# platform_designer_hps_system_hps_0_hps register map
Vendor: default_vendor.com; File version: 0.0
Registers are 32-bit, read-write, reset 0x0 unless marked. A register's access mark holds for its fields unless they carry their own. Offsets are from the block's base; [hi:lo] are bit positions; <NAME> marks a mode.

## emac0 (part 1 of 5) — Registers in the EMAC module.
Base 0xFF700000
Same registers: emac1 0xFF702000
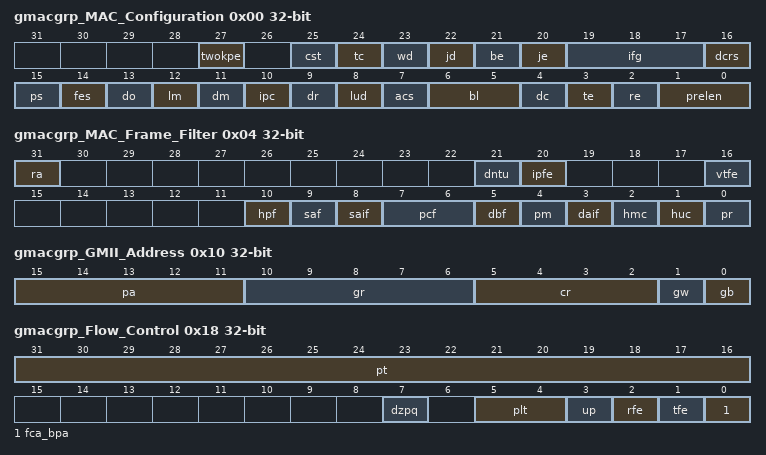
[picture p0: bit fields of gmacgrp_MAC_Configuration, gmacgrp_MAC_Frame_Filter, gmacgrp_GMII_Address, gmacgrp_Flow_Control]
0x00 gmacgrp_MAC_Configuration — The MAC Configuration register establishes receive and transmit operating modes.
  [27] twokpe — When set, the MAC considers all frames, with up to 2,000 bytes length, as normal packets. When Bit 20 (Jumbo Enable) is not set, the MAC considers all received frames of size more than 2K bytes as Giant frames. When this bit is reset and Bit 20 (Jumbo Enable) is not set, the MAC considers all received frames of size more than 1,518 bytes (1,522 bytes for tagged) as Giant frames. When Bit 20 (Jumbo Enable) is set, setting this bit has no effect on Giant Frame status.
  [25] cst — When set, the last 4 bytes (FCS) of all frames of Ether type (type field greater than 0x0600) are stripped and dropped before forwarding the frame to the application. This function is not valid when the IP Checksum Engine (Type 1) is enabled in the MAC receiver.
    0=disabled; 1=enabled
  [24] tc — When set, this bit enables the transmission of duplex mode, link speed, and link up or down information to the PHY in the RGMII. When this bit is reset, no such information is driven to the PHY.
    1=enabled; 0=disabled
  [23] wd — When this bit is set, the MAC disables the watchdog timer on the receiver. The MAC can receive frames of up to 16,384 bytes. When this bit is reset, the MAC does not allow more than 2,048 bytes (10,240 if JE is set high) of the frame being received. The MAC cuts off any bytes received after 2,048 bytes.
    0=enabled; 1=disabled
  [22] jd — When this bit is set, the MAC disables the jabber timer on the transmitter. The MAC can transfer frames of up to 16,384 bytes. When this bit is reset, the MAC cuts off the transmitter if the application sends out more than 2,048 bytes of data (10,240 if JE is set high) during transmission.
    0=enabled; 1=disabled
  [21] be — When this bit is set, the MAC allows frame bursting during transmission in the GMII half-duplex mode.
    0=disabled; 1=enabled
  [20] je — When this bit is set, the MAC allows Jumbo frames of 9,018 bytes (9,022 bytes for VLAN tagged frames) without reporting a giant frame error in the receive frame status.
    0=disabled; 1=enabled
  [19:17] ifg — These bits control the minimum IFG between frames during transmission. In the half-duplex mode, the minimum IFG can be configured only for 64 bit times (IFG = 100). Lower values are not considered. In the 1000-Mbps mode, the minimum IFG supported is 80 bit times (and above).
    0=ifg96bittimes; 1=ifg88bittimes; 2=ifg80bittimes; 3=ifg72bittimes; 4=ifg64bittimes; 5=ifg56bittimes; 6=ifg48bittimes; 7=ifg40bittimes
  [16] dcrs — When set high, this bit makes the MAC transmitter ignore the (G)MII CRS signal during frame transmission in the half-duplex mode. This request results in no errors generated because of Loss of Carrier or No Carrier during such transmission. When this bit is low, the MAC transmitter generates such errors because of Carrier Sense and can even abort the transmissions.
    0=disabled; 1=enabled
  [15] ps — This bit selects between GMII and MII
    0=gmii1000sel; 1=mii10100sel
  [14] fes — This bit selects the speed in the RMII/RGMII interface: * 0: 10 Mbps * 1: 100 Mbps This bit generates link speed encoding when TC (Bit 24) is set in the RGMII, SMII, or SGMII mode.
    0=speed10; 1=speed100
  [13] do — When this bit is set, the MAC disables the reception of frames when the gmii_txen_o is asserted in the half-duplex mode. When this bit is reset, the MAC receives all packets that are given by the PHY while transmitting. This bit is not applicable if the MAC is operating in the full-duplex mode.
    0=enabled; 1=disabled
  [12] lm — When this bit is set, the MAC operates in the loopback mode at GMII or MII. The (G)MII Receive clock input is required for the loopback to work properly, because the Transmit clock is not looped-back internally.
    0=disabled; 1=enabled
  [11] dm — When this bit is set, the MAC operates in the full-duplex mode where it can transmit and receive simultaneously.
    1=enabled; 0=disabled
  [10] ipc — When this bit is set, the MAC calculates the 16-bit ones complement of the ones complement sum of all received Ethernet frame payloads. It also checks whether the IPv4 Header checksum (assumed to be bytes 2526 or 2930 (VLAN-tagged) of the received Ethernet frame) is correct for the received frame and gives the status in the receive status word. The MAC also appends the 16-bit checksum calculated for the IP header datagram payload (bytes after the IPv4 header) and appends it to the Ethernet frame transferred to the application (when Type 2 COE is deselected). When this bit is reset, this function is disabled. When Type 2 COE is selected, this bit, when set, enables the IPv4 header checksum checking and IPv4 or IPv6 TCP, UDP, or ICMP payload checksum checking. When this bit is reset, the COE function in the receiver is disabled and the corresponding PCE and IP HCE status bits are always cleared.
    1=enabled; 0=disabled
  [9] dr — When this bit is set, the MAC attempts only one transmission. When a collision occurs on the GMII or MII interface, the MAC ignores the current frame transmission and reports a Frame Abort with excessive collision error in the transmit frame status. When this bit is reset, the MAC attempts retries based on the settings of the BL field (Bits [6:5]). This bit is applicable only in the half-duplex mode.
    1=disabled; 0=enabled
  [8] lud — This bit indicates whether the link is up or down during the transmission of configuration in the RGMII, SGMII, or SMII interface
    0=disabled; 1=enabled
  [7] acs — When this bit is set, the MAC strips the Pad or FCS field on the incoming frames only if the value of the length field is less than 1,536 bytes. All received frames with length field greater than or equal to 1,536 bytes are passed to the application without stripping the Pad or FCS field. When this bit is reset, the MAC passes all incoming frames, without modifying them, to the Host.
    0=disabled; 1=enabled
  [6:5] bl — The Back-Off limit determines the random integer number (r) of slot time delays (4,096 bit times for 1000 Mbps and 512 bit times for 10/100 Mbps) for which the MAC waits before rescheduling a transmission attempt during retries after a collision. This bit is applicable only in the half-duplex mode. * 00: k = min (n, 10) * 01: k = min (n, 8) * 10: k = min (n, 4) * 11: k = min (n, 1) where <i> n </i>= retransmission attempt. The random integer <i> r </i> takes the value in the range 0 <= r < kth power of 2
    0=backlimtr10; 1=backlimirt8; 2=backlimitr4; 3=backlimitr1
  [4] dc — When this bit is set, the deferral check function is enabled in the MAC. The MAC issues a Frame Abort status, along with the excessive deferral error bit set in the transmit frame status, when the transmit state machine is deferred for more than 24,288 bit times in the 10 or 100 Mbps mode. If the MAC is configured for 1000 Mbps operation, or if the Jumbo frame mode is enabled in the 10 or 100 Mbps mode, the threshold for deferral is 155,680 bits times. Deferral begins when the transmitter is ready to transmit, but is prevented because of an active carrier sense signal (CRS) on GMII or MII. Defer time is not cumulative. When the transmitter defers for 10,000 bit times, it transmits, collides, backs off, and then defers again after completion of back-off. The deferral timer resets to 0 and restarts. When this bit is reset, the deferral check function is disabled and the MAC defers until the CRS signal goes inactive. This bit is applicable only in the half-duplex mode.
    1=enabled; 0=disabled
  [3] te — When this bit is set, the transmit state machine of the MAC is enabled for transmission on the GMII or MII. When this bit is reset, the MAC transmit state machine is disabled after the completion of the transmission of the current frame, and does not transmit any further frames.
    0=disabled; 1=enabled
  [2] re — When this bit is set, the receiver state machine of the MAC is enabled for receiving frames from the GMII or MII. When this bit is reset, the MAC receive state machine is disabled after the completion of the reception of the current frame, and does not receive any further frames from the GMII or MII.
    0=disabled; 1=enabled
  [1:0] prelen — These bits control the number of preamble bytes that are added to the beginning of every Transmit frame. The preamble reduction occurs only when the MAC is operating
    0=pream7bytes; 1=pream5bytes; 2=pream3bytes
0x04 gmacgrp_MAC_Frame_Filter — The MAC Frame Filter register contains the filter controls for receiving frames. Some of the controls from this register go to the address check block of the MAC, which performs the first level of address filtering. The second level of filtering is performed on the incoming frame, based on other controls such as Pass Bad Frames and Pass Control Frames.
  [31] ra — When this bit is set, the MAC Receiver block passes all received frames, irrespective of whether they pass the address filter or not, to the Application. The result of the SA or DA filtering is updated (pass or fail) in the corresponding bits in the Receive Status Word. When this bit is reset, the Receiver block passes only those frames to the Application that pass the SA or DA address filter.
    0=disabled; 1=enabled
  [21] dntu — When set, this bit enables the MAC to drop the non-TCP or UDP over IP frames. The MAC forward only those frames that are processed by the Layer 4 filter. When reset, this bit enables the MAC to forward all non-TCP or UDP over IP frames.
    0=nodrop; 1=drop
  [20] ipfe — When set, this bit enables the MAC to drop frames that do not match the enabled Layer 3 and Layer 4 filters. If Layer 3 or Layer 4 filters are not enabled for matching, this bit does not have any effect. When reset, the MAC forwards all frames irrespective of the match status of the Layer 3 and Layer 4 filters.
    0=nodrop; 1=drop
  [16] vtfe — When set, this bit enables the MAC to drop VLAN tagged frames that do not match the VLAN Tag comparison. When reset, the MAC forwards all frames irrespective of the match status of the VLAN Tag.
    0=nodrop; 1=drop
  [10] hpf — When this bit is set, it configures the address filter to pass a frame if it matches either the perfect filtering or the hash filtering as set by the HMC or HUC bits. When this bit is low and the HUC or HMC bit is set, the frame is passed only if it matches the Hash filter.
    0=disabled; 1=enabled
  [9] saf — When this bit is set, the MAC compares the SA field of the received frames with the values programmed in the enabled SA registers. If the comparison matches, then the SA Match bit of RxStatus Word is set high. When this bit is set high and the SA filter fails, the MAC drops the frame. When this bit is reset, the MAC forwards the received frame to the application and with the updated SA Match bit of the RxStatus depending on the SA address comparison.
    0=disabled; 1=enabled
  [8] saif — When this bit is set, the Address Check block operates in inverse filtering mode for the SA address comparison. The frames whose SA matches the SA registers are marked as failing the SA Address filter. When this bit is reset, frames whose SA does not match the SA registers are marked as failing the SA Address filter.
    0=disabled; 1=enabled
  [7:6] pcf — These bits control the forwarding of all control frames (including unicast and multicast PAUSE frames). * 00: MAC filters all control frames from reaching the application. * 01: MAC forwards all control frames except PAUSE control frames to application even if they fail the Address filter. * 10: MAC forwards all control frames to application even if they fail the Address Filter. * 11: MAC forwards control frames that pass the Address Filter. The following conditions should be true for the PAUSE control frames processing: * Condition 1: The MAC is in the full-duplex mode and flow control is enabled by setting Bit 2 (RFE) of Register 6 (Flow Control Register) to 1. * Condition 2: The destination address (DA) of the received frame matches the special multicast address or the MAC Address 0 when Bit 3 (UP) of the Register 6 (Flow Control Register) is set. * Condition 3: The Type field of the received frame is 0x8808 and the OPCODE field is 0x0001. This field should be set to 01 only when the Condition 1 is true, that is, the MAC is programmed to operate in the full-duplex mode and the RFE bit is enabled. Otherwise, the PAUSE frame filtering may be inconsistent. When Condition 1 is false, the PAUSE frames are considered as generic control frames. Therefore, to pass all control frames (including PAUSE control frames) when the full-duplex mode and flow control is not enabled, you should set the PCF field to 10 or 11 (as required by the application).
    0=macfltallcfr; 1=macfwdxpause; 2=macfwdfail; 3=macfwdpass
  [5] dbf — When this bit is set, the AFM block filters all incoming broadcast frames. In addition, it overrides all other filter settings. When this bit is reset, the AFM block passes all received broadcast frames.
    0=disabled; 1=enabled
  [4] pm — When set, this bit indicates that all received frames with a multicast destination address (first bit in the destination address field is '1') are passed. When reset, filtering of multicast frame depends on HMC bit.
    0=disabled; 1=enabled
  [3] daif — When this bit is set, the Address Check block operates in inverse filtering mode for the DA address comparison for both unicast and multicast frames. When reset, normal filtering of frames is performed.
    0=disabled; 1=enabled
  [2] hmc — When set, MAC performs destination address filtering of received multicast frames according to the hash table. When reset, the MAC performs a perfect destination address filtering for multicast frames, that is, it compares the DA field with the values programmed in DA registers.
    0=disabled; 1=enabled
  [1] huc — When set, MAC performs destination address filtering of unicast frames according to the hash table. When reset, the MAC performs a perfect destination address filtering for unicast frames, that is, it compares the DA field with the values programmed in DA registers.
    1=enabled; 0=disabled
  [0] pr — When this bit is set, the Address Filter block passes all incoming frames regardless of its destination or source address. The SA or DA Filter Fails status bits of the Receive Status Word are always cleared when PR is set.
    1=enabled; 0=disabled
0x10 gmacgrp_GMII_Address — The GMII Address register controls the management cycles to the external PHY through the management interface.
  [15:11] pa — This field indicates which of the 32 possible PHY devices are being accessed. For RevMII, this field gives the PHY Address of the RevMII block.
  [10:6] gr — These bits select the desired GMII register in the selected PHY device. For RevMII, these bits select the desired CSR register in the RevMII Registers set.
  [5:2] cr — The CSR Clock Range selection determines the frequency of the MDC clock according to the l3_sp_clk frequency used in your design. The suggested range of l3_sp_clk frequency applicable for each value (when Bit[5] = 0) ensures that the MDC clock is approximately between the frequency range 1.0 MHz - 2.5 MHz. When Bit 5 is set, you can achieve MDC clock of frequency higher than the IEEE 802.3 specified frequency limit of 2.5 MHz and program a clock divider of lower value. For example, when l3_sp_clk is of 100 MHz frequency and you program these bits as 1010, then the resultant MDC clock is of 12.5 MHz which is outside the limit of IEEE 802.3 specified range. Only use the values larger than 7 if the interfacing chips support faster MDC clocks.
    0=div42; 1=div62; 2=div16; 3=div26; 4=div102; 5=div124; 8=div4; 9=div6; 10=div8; 11=div10; 12=div12; 13=div14; 14=div16again; 15=div18
  [1] gw — When set, this bit indicates to the PHY or RevMII that this is a Write operation using the GMII Data register. If this bit is not set, it indicates that this is a Read operation, that is, placing the data in the GMII Data register.
    0=disabled; 1=enabled
  [0] gb — This bit should read logic 0 before writing to Register 4 and Register 5. During a PHY or RevMII register access, the software sets this bit to 1'b1 to indicate that a Read or Write access is in progress. The Register 5 is invalid until this bit is cleared by the MAC. Therefore, Register 5 (GMII Data) should be kept valid until the MAC clears this bit during a PHY Write operation. Similarly for a read operation, the contents of Register 5 are not valid until this bit is cleared. The subsequent read or write operation should happen only after the previous operation is complete. Because there is no acknowledgment from the PHY to MAC after a read or write operation is completed, there is no change in the functionality of this bit even when the PHY is not present.
    0=disabled; 1=enabled
0x14 gmacgrp_GMII_Data — The GMII Data register stores Write data to be written to the PHY register located at the address specified in Register 4 (GMII Address Register). This register also stores the Read data from the PHY register located at the address specified by Register 4.
  [15:0] gd — This field contains the 16-bit data value read from the PHY or RevMII after a Management Read operation or the 16-bit data value to be written to the PHY or RevMII before a Management Write operation.
0x18 gmacgrp_Flow_Control — The Flow Control register controls the generation and reception of the Control (Pause Command) frames by the MAC's Flow control block. A Write to a register with the Busy bit set to '1' triggers the Flow Control block to generate a Pause Control frame. The fields of the control frame are selected as specified in the 802.3x specification, and the Pause Time value from this register is used in the Pause Time field of the control frame. The Busy bit remains set until the control frame is transferred onto the cable. The Host must make sure that the Busy bit is cleared before writing to the register.
  [31:16] pt — This field holds the value to be used in the Pause Time field in the transmit control frame. Because the Pause Time bits are double-synchronized to the (G)MII clock domain, then consecutive writes to this register should be performed only after at least four clock cycles in the destination clock domain.
  [7] dzpq — When this bit is set, it disables the automatic generation of the Zero-Quanta Pause Control frames on the de-assertion of the flow-control signal from the FIFO layer (MTL or external sideband flow control signal sbd_flowctrl_i/mti_flowctrl_i). When this bit is reset, normal operation with automatic Zero-Quanta Pause Control frame generation is enabled.
    1=enabled; 0=disabled
  [5:4] plt — This field configures the threshold of the PAUSE timer at which the input flow control signal mti_flowctrl_i (or sbd_flowctrl_i) is checked for automatic retransmission of PAUSE Frame. The threshold values should be always less than the Pause Time configured in Bits[31:16]. For example, if PT = 100H (256 slot-times), and PLT = 01, then a second PAUSE frame is automatically transmitted if the mti_flowctrl_i signal is asserted at 228 (256 - 28) slot times after the first PAUSE frame is transmitted. The slot time is defined as the time taken to transmit 512 bits (64 bytes) on the GMII or MII interface.
    0=pausetime_4; 1=pausetime_28; 2=pausetime_144; 3=pausetime_256
  [3] up — When this bit is set, then in addition to the detecting Pause frames with the unique multicast address, the MAC detects the Pause frames with the station's unicast address specified in the MAC Address0 High Register and MAC Address0 Low Register. When this bit is reset, the MAC detects only a Pause frame with the unique multicast address specified in the 802.3x standard.
    0=disabled; 1=enabled
  [2] rfe — When this bit is set, the MAC decodes the received Pause frame and disables its transmitter for a specified (Pause) time. When this bit is reset, the decode function of the Pause frame is disabled.
    0=disabled; 1=enabled
  [1] tfe — In the full-duplex mode, when this bit is set, the MAC enables the flow control operation to transmit Pause frames. When this bit is reset, the flow control operation in the MAC is disabled, and the MAC does not transmit any Pause frames. In half-duplex mode, when this bit is set, the MAC enables the back-pressure operation. When this bit is reset, the back-pressure feature is disabled.
    0=disabled; 1=enabled
  [0] fca_bpa — This bit initiates a Pause Control frame in the full-duplex mode and activates the backpressure function in the half-duplex mode if the TFE bit is set. In the full-duplex mode, this bit should be read as 1'b0 before writing to the Flow Control register. To initiate a Pause control frame, the Application must set this bit to 1'b1. During a transfer of the Control Frame, this bit continues to be set to signify that a frame transmission is in progress. After the completion of Pause control frame transmission, the MAC resets this bit to 1'b0. The Flow Control register should not be written to until this bit is cleared. In the half-duplex mode, when this bit is set (and TFE is set), then backpressure is asserted by the MAC. During backpressure, when the MAC receives a new frame, the transmitter starts sending a JAM pattern resulting in a collision. This control register bit is logically ORed with the mti_flowctrl_i input signal for the backpressure function. When the MAC is configured for the full-duplex mode, the BPA is automatically disabled.
    0=disabled; 1=enabled
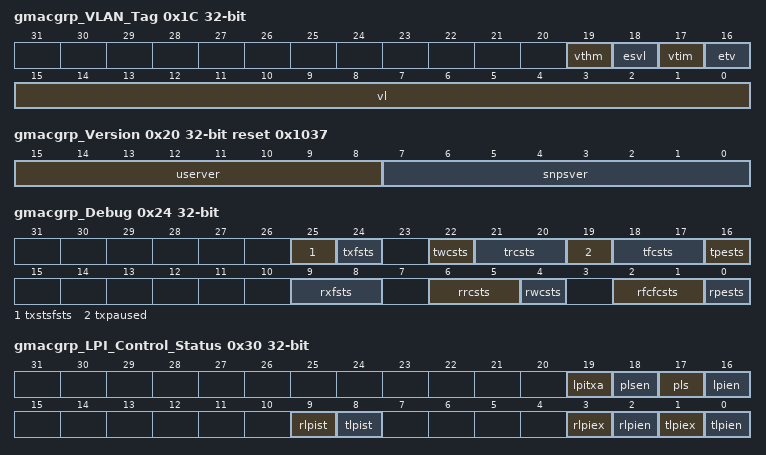
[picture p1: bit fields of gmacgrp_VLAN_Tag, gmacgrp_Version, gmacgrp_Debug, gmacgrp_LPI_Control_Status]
0x1C gmacgrp_VLAN_Tag — The VLAN Tag register contains the IEEE 802.1Q VLAN Tag to identify the VLAN frames. The MAC compares the 13th and 14th bytes of the receiving frame (Length/Type) with 16'h8100, and the following two bytes are compared with the VLAN tag. If a match occurs, the MAC sets the received VLAN bit in the receive frame status. The legal length of the frame is increased from 1,518 bytes to 1,522 bytes. Because the VLAN Tag register is double-synchronized to the (G)MII clock domain, then consecutive writes to these register should be performed only after at least four clock cycles in the destination clock domain.
  [19] vthm — When set, the most significant four bits of the VLAN tag's CRC are used to index the content of Register 354 (VLAN Hash Table Register). A value of 1 in the VLAN Hash Table register, corresponding to the index, indicates that the frame matched the VLAN hash table. When Bit 16 (ETV) is set, the CRC of the 12-bit VLAN Identifier (VID) is used for comparison whereas when ETV is reset, the CRC of the 16-bit VLAN tag is used for comparison. When reset, the VLAN Hash Match operation is not performed.
  [18] esvl — When this bit is set, the MAC transmitter and receiver also consider the S-VLAN (Type = 0x88A8) frames as valid VLAN tagged frames.
  [17] vtim — When set, this bit enables the VLAN Tag inverse matching. The frames that do not have matching VLAN Tag are marked as matched. When reset, this bit enables the VLAN Tag perfect matching. The frames with matched VLAN Tag are marked as matched.
  [16] etv — When this bit is set, a 12-bit VLAN identifier is used for comparing and filtering instead of the complete 16-bit VLAN tag. Bits [11:0] of VLAN tag are compared with the corresponding field in the received VLAN-tagged frame. Similarly, when enabled, only 12 bits of the VLAN tag in the received frame are used for hash-based VLAN filtering. When this bit is reset, all 16 bits of the 15th and 16th bytes of the received VLAN frame are used for comparison and VLAN hash filtering.
    0=disabled; 1=enabled
  [15:0] vl — This field contains the 802.1Q VLAN tag to identify the VLAN frames and is compared to the 15th and 16th bytes of the frames being received for VLAN frames. The following list describes the bits of this field: * Bits [15:13]: User Priority * Bit 12: Canonical Format Indicator (CFI) or Drop Eligible Indicator (DEI) * Bits[11:0]: VLAN tag's VLAN Identifier (VID) field When the ETV bit is set, only the VID (Bits[11:0]) is used for comparison. If VL (VL[11:0] if ETV is set) is all zeros, the MAC does not check the fifteenth and 16th bytes for VLAN tag comparison, and declares all frames with a Type field value of 0x8100 or 0x88a8 as VLAN frames.
0x20 gmacgrp_Version ro reset 0x1037 — The Version registers identifies the version of the EMAC. This register contains two bytes: one specified by Synopsys to identify the core release number, and the other specified by Altera.
  [15:8] userver — Altera-defined Version
  [7:0] snpsver — Synopsys-defined Version (3.7)
0x24 gmacgrp_Debug ro — The Debug register gives the status of all main blocks of the transmit and receive data-paths and the FIFOs. An all-zero status indicates that the MAC is in idle state (and FIFOs are empty) and no activity is going on in the data-paths.
  [25] txstsfsts — When high, this bit indicates that the MTL TxStatus FIFO is full. Therefore, the MTL cannot accept any more frames for transmission.
    0=inactive; 1=active
  [24] txfsts — When high, this bit indicates that the MTL Tx FIFO is not empty and some data is left for transmission.
    0=inactive; 1=active
  [22] twcsts — When high, this bit indicates that the MTL Tx FIFO Write Controller is active and transferring data to the Tx FIFO.
    0=inactive; 1=active
  [21:20] trcsts — This field indicates the state of the Tx FIFO Read Controller
    0=idle; 1=readstate; 2=waittxstat; 3=wrtxstat
  [19] txpaused — When high, this bit indicates that the MAC transmitter is in the PAUSE condition (in the full-duplex only mode) and hence does not schedule any frame for transmission.
    0=disable; 1=enabled
  [18:17] tfcsts — This field indicates the state of the MAC Transmit Frame Controller block
    0=idle; 1=waitifg; 2=xtpause; 3=xtinfrm
  [16] tpests — When high, this bit indicates that the MAC GMII or MII transmit protocol engine is actively transmitting data and is not in the IDLE state.
    0=disabled; 1=enabled
  [9:8] rxfsts — This field gives the status of the fill-level of the Rx FIFO.
    0=rxfifoempty; 1=rxfifobellvl; 2=rxfifoablvl; 3=rxfifofull
  [6:5] rrcsts — This field gives the state of the Rx FIFO read Controller
    0=idle; 1=rdframedata; 2=rdframestat; 3=flushfrds
  [4] rwcsts — When high, this bit indicates that the MTL Rx FIFO Write Controller is active and is transferring a received frame to the FIFO.
    0=inactive; 1=active
  [2:1] rfcfcsts — When high, this field indicates the active state of the small FIFO Read and Write controllers of the MAC Receive Frame Controller Module.
    0=inactive; 1=active
  [0] rpests — When high, this bit indicates that the MAC GMII or MII receive protocol engine is actively receiving data and not in IDLE state.
    0=inactive; 1=active
0x30 gmacgrp_LPI_Control_Status — The LPI Control and Status Register controls the LPI functions and provides the LPI interrupt status. The status bits are cleared when this register is read.
  [19] lpitxa — This bit controls the behavior of the MAC when it is entering or coming out of the LPI mode on the transmit side. This bit is not functional in the GMAC-CORE configuration in which the Tx clock gating is done during the LPI mode. If the LPITXA and LPIEN bits are set to 1, the MAC enters the LPI mode only after all outstanding frames (in the core) and pending frames (in the application interface) have been transmitted. The MAC comes out of the LPI mode when the application sends any frame for transmission or the application issues a TX FIFO Flush command. In addition, the MAC automatically clears the LPIEN bit when it exits the LPI state. If TX FIFO Flush is set, in Bit 20 of Register 6 (Operation Mode Register), when the MAC is in the LPI mode, the MAC exits the LPI mode. When this bit is 0, the LPIEN bit directly controls behavior of the MAC when it is entering or coming out of the LPI mode.
    0=disabled; 1=enabled
  [18] plsen — This bit enables the link status received on the RGMII receive paths to be used for activating the LPI LS TIMER. When set, the MAC uses the link-status bits of Register 54 (SGMII/RGMII/SMII Status Register) and Bit 17 (PLS) for the LPI LS Timer trigger. When cleared, the MAC ignores the link-status bits of Register 54 and takes only the PLS bit.
    0=disabled; 1=enabled
  [17] pls — This bit indicates the link status of the PHY. The MAC Transmitter asserts the LPI pattern only when the link status is up (okay) at least for the time indicated by the LPI LS TIMER. When set, the link is considered to be okay (up) and when reset, the link is considered to be down.
    0=disabled; 1=enabled
  [16] lpien — When set, this bit instructs the MAC Transmitter to enter the LPI state. When reset, this bit instructs the MAC to exit the LPI state and resume normal transmission. This bit is cleared when the LPITXA bit is set and the MAC exits the LPI state because of the arrival of a new packet for transmission.
    0=disabled; 1=enabled
  [9] rlpist ro — When set, this bit indicates that the MAC is receiving the LPI pattern on the GMII or MII interface.
    0=inactive; 1=active
  [8] tlpist ro — When set, this bit indicates that the MAC is transmitting the LPI pattern on the GMII or MII interface.
    0=inactive; 1=active
  [3] rlpiex ro — When set, this bit indicates that the MAC Receiver has stopped receiving the LPI pattern on the GMII or MII interface, exited the LPI state, and resumed the normal reception. This bit is cleared by a read into this register. Note: This bit may not get set if the MAC stops receiving the LPI pattern for a very short duration, such as, less than 3 clock cycles of l3_sp_clk.
    0=inactive; 1=active
  [2] rlpien ro — When set, this bit indicates that the MAC Receiver has received an LPI pattern and entered the LPI state. This bit is cleared by a read into this register. Note: This bit may not get set if the MAC stops receiving the LPI pattern for a very short duration, such as, less than 3 clock cycles of l3_sp_clk.
    0=inactive; 1=active
  [1] tlpiex ro — When set, this bit indicates that the MAC transmitter has exited the LPI state after the user has cleared the LPIEN bit and the LPI TW Timer has expired. This bit is cleared by a read into this register.
    0=inactive; 1=active
  [0] tlpien ro — When set, this bit indicates that the MAC Transmitter has entered the LPI state because of the setting of the LPIEN bit. This bit is cleared by a read into this register.
    0=inactive; 1=active
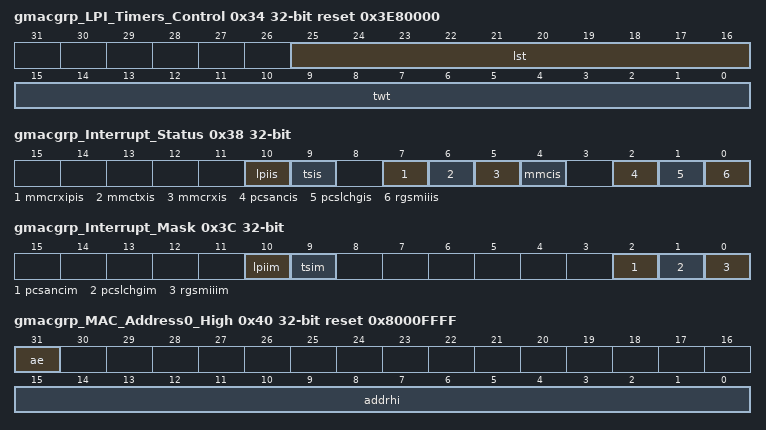
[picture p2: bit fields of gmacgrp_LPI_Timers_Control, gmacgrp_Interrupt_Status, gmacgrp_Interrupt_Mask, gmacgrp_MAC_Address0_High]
0x34 gmacgrp_LPI_Timers_Control reset 0x3E80000 — The LPI Timers Control register controls the timeout values in the LPI states. It specifies the time for which the MAC transmits the LPI pattern and also the time for which the MAC waits before resuming the normal transmission.
  [25:16] lst — This field specifies the minimum time (in milliseconds) for which the link status from the PHY should be up (OKAY) before the LPI pattern can be transmitted to the PHY. The MAC does not transmit the LPI pattern even when the LPIEN bit is set unless the LPI LS Timer reaches the programmed terminal count. The default value of the LPI LS Timer is 1000 (1 sec) as defined in the IEEE standard.
  [15:0] twt — This field specifies the minimum time (in microseconds) for which the MAC waits after it stops transmitting the LPI pattern to the PHY and before it resumes the normal transmission. The TLPIEX status bit is set after the expiry of this timer.
0x38 gmacgrp_Interrupt_Status ro — The Interrupt Status register identifies the events in the MAC that can generate interrupt. All interrupt events are generated only when the corresponding optional feature is enabled.
  [10] lpiis — This bit is set for any LPI state entry or exit in the MAC Transmitter or Receiver. This bit is cleared on reading Bit 0 of Register 12 (LPI Control and Status Register). In all other modes, this bit is reserved.
    0=inactive; 1=active
  [9] tsis — This bit is set when any of the following conditions is true: * The system time value equals or exceeds the value specified in the Target Time High and Low registers. * There is an overflow in the seconds register. * The Auxiliary snapshot trigger is asserted. This bit is cleared on reading Bit 0 of the Register 458 (Timestamp Status Register). When set, this bit indicates that the system time value is equal to or exceeds the value specified in the Target Time registers. In this mode, this bit is cleared after the completion of the read of this bit. In all other modes, this bit is reserved.
    0=inactive; 1=active
  [7] mmcrxipis — This bit is set high when an interrupt is generated in the MMC Receive Checksum Offload Interrupt Register. This bit is cleared when all the bits in this interrupt register are cleared.
    0=inactive; 1=active
  [6] mmctxis — This bit is set high when an interrupt is generated in the MMC Transmit Interrupt Register. This bit is cleared when all the bits in this interrupt register are cleared.
    0=inactive; 1=active
  [5] mmcrxis — This bit is set high when an interrupt is generated in the MMC Receive Interrupt Register. This bit is cleared when all the bits in this interrupt register are cleared.
    0=disabled; 1=enabled
  [4] mmcis — This bit is set high when any of the Bits [7:5] is set high and cleared only when all of these bits are low.
    0=inactive; 1=active
  [2] pcsancis — This bit is set when the Auto-negotiation is completed in the TBI, RTBI, or SGMII PHY interface (Bit 5 in Register 49 (AN Status Register)). This bit is cleared when you perform a read operation to the AN Status register. This bit is valid only when you select the SGMII PHY interface during operation.
  [1] pcslchgis — This bit is set because of any change in Link Status in the TBI, RTBI, or SGMII PHY interface (Bit 2 in Register 49 (AN Status Register)). This bit is cleared when you perform a read operation on the AN Status register. This bit is valid only when you select the SGMII PHY interface during operation.
  [0] rgsmiiis — This bit is set because of any change in value of the Link Status of RGMII or SMII interface (Bit 3 in Register 54 (SGMII/RGMII/SMII Status Register)). This bit is cleared when you perform a read operation on the SGMII/RGMII/SMII Status Register.
    0=inactive; 1=active
0x3C gmacgrp_Interrupt_Mask — The Interrupt Mask Register bits enable you to mask the interrupt signal because of the corresponding event in the Interrupt Status Register. The interrupt signal is sbd_intr_o.
  [10] lpiim — When set, this bit disables the assertion of the interrupt signal because of the setting of the LPI Interrupt Status bit in Register 14 (Interrupt Status Register).
    0=disabled; 1=enabled
  [9] tsim — When set, this bit disables the assertion of the interrupt signal because of the setting of Timestamp Interrupt Status bit in Register 14 (Interrupt Status Register).
    0=disabled; 1=enabled
  [2] pcsancim ro — When set, this bit disables the assertion of the interrupt signal because of the setting of PCS Auto-negotiation complete bit in Register 14 (Interrupt Status Register).
  [1] pcslchgim ro — When set, this bit disables the assertion of the interrupt signal because of the setting of the PCS Link-status changed bit in Register 14 (Interrupt Status Register).
  [0] rgsmiiim — When set, this bit disables the assertion of the interrupt signal because of the setting of the RGMII or SMII Interrupt Status bit in Register 14 (Interrupt Status Register).
    0=disabled; 1=enabled
0x40 gmacgrp_MAC_Address0_High reset 0x8000FFFF — The MAC Address0 High register holds the upper 16 bits of the first 6-byte MAC address of the station. The first DA byte that is received on the (G)MII interface corresponds to the LS byte (Bits [7:0]) of the MAC Address Low register. For example, if 0x112233445566 is received (0x11 in lane 0 of the first column) on the (G)MII as the destination address, then the MacAddress0 Register [47:0] is compared with 0x665544332211. Because the MAC address registers are double-synchronized to the (G)MII clock domains, then the synchronization is triggered only when Bits[31:24] (in little-endian mode) or Bits[7:0] (in big-endian mode) of the MAC Address0 Low Register are written. For proper synchronization updates, the consecutive writes to this Address Low Register should be performed after at least four clock cycles in the destination clock domain.
  [31] ae ro — This bit is always set to 1.
  [15:0] addrhi — This field contains the upper 16 bits (47:32) of the first 6-byte MAC address. The MAC uses this field for filtering the received frames and inserting the MAC address in the Transmit Flow Control (PAUSE) Frames.
